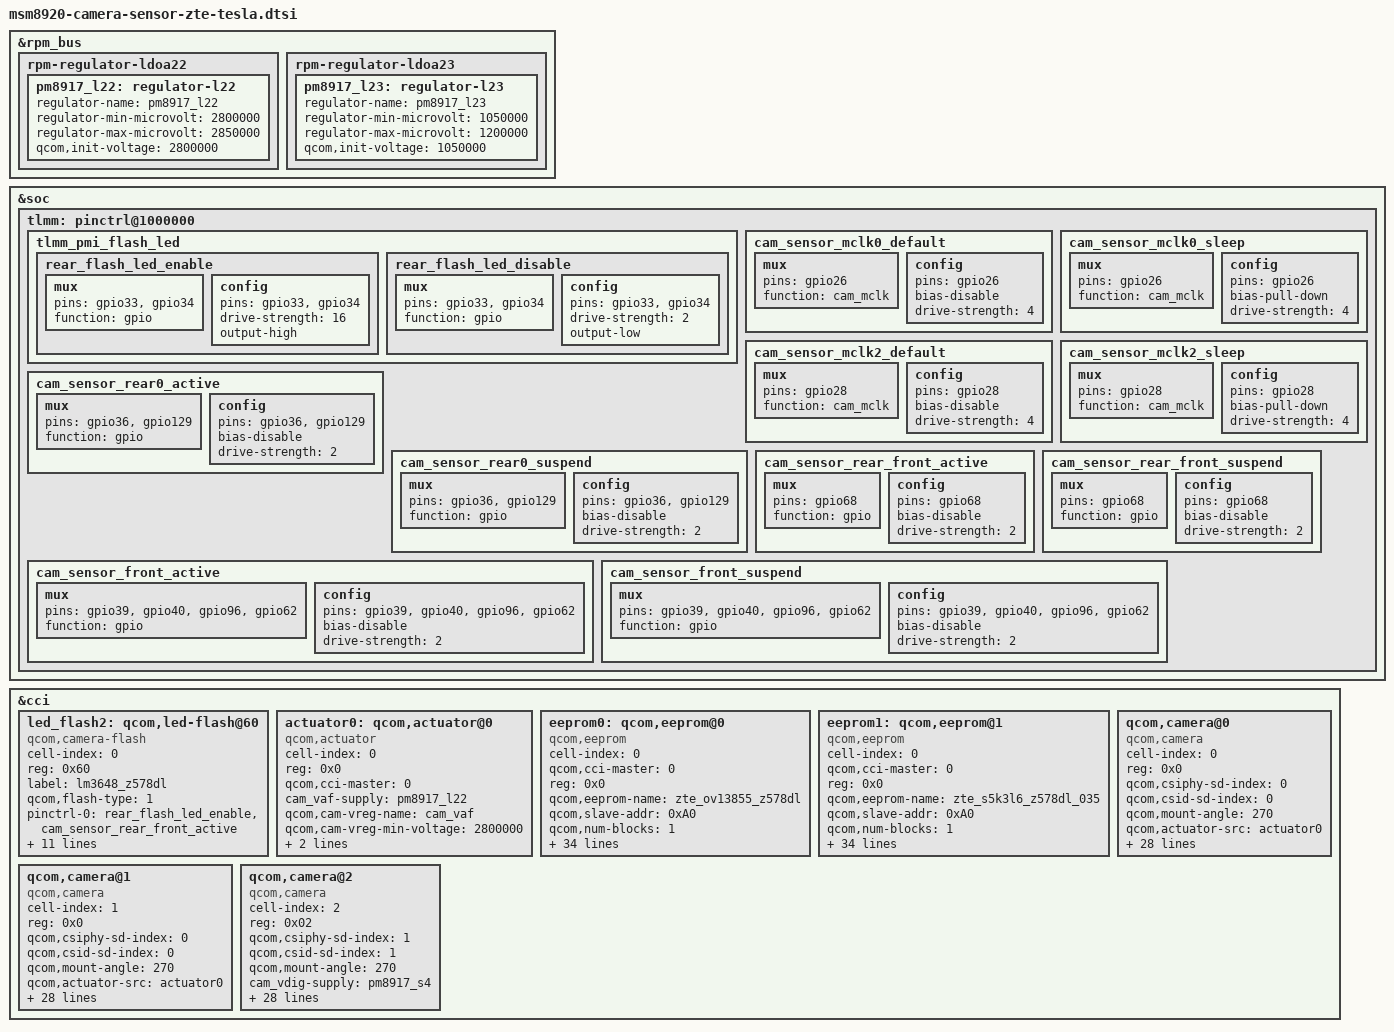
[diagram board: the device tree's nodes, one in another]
/*
* Copyright (c) 2015-2016, The Linux Foundation. All rights reserved.
*
* This program is free software; you can redistribute it and/or modify
* it under the terms of the GNU General Public License version 2 and
* only version 2 as published by the Free Software Foundation.
*
* This program is distributed in the hope that it will be useful,
* but WITHOUT ANY WARRANTY; without even the implied warranty of
* MERCHANTABILITY or FITNESS FOR A PARTICULAR PURPOSE.  See the
* GNU General Public License for more details.
*/
&rpm_bus {
	rpm-regulator-ldoa22 {
			status = "okay";
			pm8917_l22: regulator-l22 {
				regulator-name = "pm8917_l22";
				regulator-min-microvolt = <2800000>;
				regulator-max-microvolt = <2850000>;
				qcom,init-voltage = <2800000>;
				status = "okay";
			};
		};
		rpm-regulator-ldoa23 {
			status = "okay";
			pm8917_l23: regulator-l23 {
				regulator-name = "pm8917_l23";
				regulator-min-microvolt = <1050000>;
				regulator-max-microvolt = <1200000>;
				qcom,init-voltage = <1050000>;
				status = "okay";
			};
		};

};
&soc {
	tlmm: pinctrl@1000000 {
		tlmm_pmi_flash_led {
			rear_flash_led_enable: rear_flash_led_enable {
				mux {
					pins = "gpio33","gpio34";
					function = "gpio";
				};

				config {
					pins = "gpio33","gpio34";
					drive-strength = <16>;
					output-high;
				};
			};
			rear_flash_led_disable: rear_flash_led_disable {
				mux {
					pins = "gpio33","gpio34";
					function = "gpio";
				};

				config {
					pins = "gpio33","gpio34";
					drive-strength = <2>;
					output-low;
				};
			};
		};
		/*sensors */
	cam_sensor_mclk0_default: cam_sensor_mclk0_default {
		/* MCLK0 */
		mux {
			/* CLK, DATA */
			pins = "gpio26";
			function = "cam_mclk";
		};
		config {
			pins = "gpio26";
			bias-disable; /* No PULL */
			drive-strength = <4>; /* 4 MA */
		};
	};
	cam_sensor_mclk0_sleep: cam_sensor_mclk0_sleep {
		/* MCLK0 */
		mux {
			/* CLK, DATA */
			pins = "gpio26";
			function = "cam_mclk";
		};
		config {
			pins = "gpio26";
			bias-pull-down; /* PULL DOWN */
			drive-strength = <4>; /* 4 MA */
		};
	};
		cam_sensor_mclk2_default: cam_sensor_mclk2_default {
			/* MCLK2 */
			mux {
				/* CLK, DATA */
				pins = "gpio28";
				function = "cam_mclk";
			};
			config {
				pins = "gpio28";
				bias-disable; /* No PULL */
				drive-strength = <4>; /* 4 MA */
			};
		};
		cam_sensor_mclk2_sleep: cam_sensor_mclk2_sleep {
			/* MCLK2 */
			mux {
				/* CLK, DATA */
				pins = "gpio28";
				function = "cam_mclk";
			};
			config {
				pins = "gpio28";
				bias-pull-down; /* PULL DOWN */
				drive-strength = <4>; /* 4 MA */
			};
		};
		cam_sensor_rear0_active: cam_sensor_rear0_active {
			mux {
				pins = "gpio36",  "gpio129";
				function = "gpio";
			};

			config {
				pins = "gpio36",  "gpio129";
				bias-disable; /* No PULL */
				drive-strength = <2>; /* 2 MA */
			};
		};

		cam_sensor_rear0_suspend: cam_sensor_rear0_suspend{
			mux {
				pins = "gpio36",  "gpio129";
				function = "gpio";
			};

			config {
				pins = "gpio36", "gpio129";
				bias-disable; /* No PULL */
				drive-strength = <2>; /* 2 MA */
			};
		};

		cam_sensor_rear_front_active: cam_sensor_rear_front_active {
			mux {
				pins = "gpio68";
				function = "gpio";
			};

			config {
				pins = "gpio68";
				bias-disable; /* No PULL */
				drive-strength = <2>; /* 2 MA */
			};
		};

		cam_sensor_rear_front_suspend: cam_sensor_rear_front_suspend{
			mux {
				pins = "gpio68";
				function = "gpio";
			};

			config {
				pins = "gpio68";
				bias-disable; /* No PULL */
				drive-strength = <2>; /* 2 MA */
			};
		};
		cam_sensor_front_active: cam_sensor_front_active {
			mux {
				pins = "gpio39", "gpio40", "gpio96","gpio62";
				function = "gpio";
			};

			config {
				pins = "gpio39", "gpio40", "gpio96","gpio62";
				bias-disable; /* No PULL */
				drive-strength = <2>; /* 2 MA */
			};
		};

		cam_sensor_front_suspend: cam_sensor_front_suspend{
			mux {
				pins = "gpio39", "gpio40", "gpio96","gpio62";
				function = "gpio";
			};

			config {
				pins = "gpio39", "gpio40", "gpio96","gpio62";
				bias-disable; /* No PULL */
				drive-strength = <2>; /* 2 MA */
			};
		};
	};
};



&cci {
	led_flash2: qcom,led-flash@60{
		cell-index = <0>;
		compatible = "qcom,camera-flash";
		reg = <0x60>;
		label = "lm3648_z578dl";
		qcom,flash-type = <1>;
		pinctrl-names = "cam_default", "cam_suspend";
		pinctrl-0 = <&rear_flash_led_enable
				&cam_sensor_rear_front_active>;
		pinctrl-1 = <&rear_flash_led_disable
				&cam_sensor_rear_front_suspend>;
		gpios = <&tlmm 33 0>,
			<&tlmm 34 0>,
			<&tlmm 68 0>;
		qcom,gpio-flash-en = <0>;
		qcom,gpio-flash-now = <1>;
		qcom,gpio-flash-reset = <2>;
		qcom,gpio-req-tbl-num = <0 1 2>;
		qcom,gpio-req-tbl-flags = <0 0 0>;
		qcom,gpio-req-tbl-label = "FLASH_EN",
			"FLASH_NOW",
			"FLASH_RESET";
		qcom,cci-master = <0>;
	};
	actuator0: qcom,actuator@0 {
		cell-index = <0>;
		reg = <0x0>;
		compatible = "qcom,actuator";
		qcom,cci-master = <0>;
		cam_vaf-supply = <&pm8917_l22>;
		qcom,cam-vreg-name = "cam_vaf";
		qcom,cam-vreg-min-voltage = <2800000>;
		qcom,cam-vreg-max-voltage = <2850000>;
		qcom,cam-vreg-op-mode = <100000>;
	};
	eeprom0: qcom,eeprom@0 {
		cell-index = <0>;
		qcom,cci-master = <0>;
		reg = <0x0>;
		qcom,eeprom-name = "zte_ov13855_z578dl";
		compatible = "qcom,eeprom";
		qcom,slave-addr = <0xA0>;
		qcom,num-blocks = <1>;
		qcom,page0 = <0 0x0 2 0x0 1 0>;
		qcom,poll0 = <0 0x0 2 0x0 1 0>;
		qcom,mem0 = <3616 0x0000 2 0x0 1 0>;
		cam_vdig-supply = <&pm8917_l23>;
		qcom,cam-vreg-name ="cam_vaf","cam_vdig";
		qcom,cam-vreg-min-voltage = <2850000 1050000>;
		qcom,cam-vreg-max-voltage = <2850000 1050000>;
		qcom,cam-vreg-op-mode = <100000 105000>;
		pinctrl-names = "cam_default", "cam_suspend";
		pinctrl-0 = <&cam_sensor_mclk0_default
				&cam_sensor_rear_front_active
				&cam_sensor_rear0_active>;
		pinctrl-1 = <&cam_sensor_mclk0_sleep
				&cam_sensor_rear_front_suspend
				&cam_sensor_rear0_suspend>;
		gpios = <&tlmm 26 0>,
			<&tlmm 36 0>,
			<&tlmm 68 0>,
			<&tlmm 129 0>;
		qcom,gpio-reset = <1>;
		qcom,gpio-vio = <2>;
		qcom,gpio-vana = <3>;
		qcom,gpio-req-tbl-num = <0 1 2 3>;
		qcom,gpio-req-tbl-flags = <1 0 0 0>;
		qcom,gpio-req-tbl-label = "CAMIF_MCLK0",
			"CAM_RESET0",
			"CAM_VIO0",
			"CAM_VANA0";
		qcom,cam-power-seq-type = "sensor_gpio","sensor_gpio","sensor_gpio",
			"sensor_vreg","sensor_vreg","sensor_clk","sensor_gpio";
		qcom,cam-power-seq-val = "sensor_gpio_reset","sensor_gpio_vana","sensor_gpio_vio",
			"cam_vdig","cam_vaf","sensor_cam_mclk","sensor_gpio_reset";
		qcom,cam-power-seq-cfg-val = <0 1 1 0 0 24000000 1>;
		qcom,cam-power-seq-delay = <1 0 0 0 1 1 10>;
		status = "ok";
		clocks = <&clock_gcc clk_mclk0_clk_src>,
				<&clock_gcc clk_gcc_camss_mclk0_clk>;
		clock-names = "cam_src_clk", "cam_clk";
		qcom,clock-rates = <24000000 0>;
	};
	eeprom1: qcom,eeprom@1 {
		cell-index = <0>;
		qcom,cci-master = <0>;
		reg = <0x0>;
		qcom,eeprom-name = "zte_s5k3l6_z578dl_035";
		compatible = "qcom,eeprom";
		qcom,slave-addr = <0xA0>;
		qcom,num-blocks = <1>;
		qcom,page0 = <0 0x0 2 0x0 1 0>;
		qcom,poll0 = <0 0x0 2 0x0 1 0>;
		qcom,mem0 = <3616 0x0000 2 0x0 1 0>;
		cam_vdig-supply = <&pm8917_l23>;
		qcom,cam-vreg-name ="cam_vaf","cam_vdig";
		qcom,cam-vreg-min-voltage = <2850000 1050000>;
		qcom,cam-vreg-max-voltage = <2850000 1050000>;
		qcom,cam-vreg-op-mode = <100000 105000>;
		pinctrl-names = "cam_default", "cam_suspend";
		pinctrl-0 = <&cam_sensor_mclk0_default
				&cam_sensor_rear_front_active
				&cam_sensor_rear0_active>;
		pinctrl-1 = <&cam_sensor_mclk0_sleep
				&cam_sensor_rear_front_suspend
				&cam_sensor_rear0_suspend>;
		gpios = <&tlmm 26 0>,
			<&tlmm 36 0>,
			<&tlmm 68 0>,
			<&tlmm 129 0>;
		qcom,gpio-reset = <1>;
		qcom,gpio-vio = <2>;
		qcom,gpio-vana = <3>;
		qcom,gpio-req-tbl-num = <0 1 2 3>;
		qcom,gpio-req-tbl-flags = <1 0 0 0>;
		qcom,gpio-req-tbl-label = "CAMIF_MCLK0",
			"CAM_RESET0",
			"CAM_VIO0",
			"CAM_VANA0";
		qcom,cam-power-seq-type = "sensor_gpio","sensor_gpio","sensor_gpio",
			"sensor_vreg","sensor_vreg","sensor_clk","sensor_gpio";
		qcom,cam-power-seq-val = "sensor_gpio_reset","sensor_gpio_vana","sensor_gpio_vio",
			"cam_vdig","cam_vaf","sensor_cam_mclk","sensor_gpio_reset";
		qcom,cam-power-seq-cfg-val = <0 1 1 0 0 24000000 1>;
		qcom,cam-power-seq-delay = <1 0 0 0 1 1 10>;
		status = "ok";
		clocks = <&clock_gcc clk_mclk0_clk_src>,
				<&clock_gcc clk_gcc_camss_mclk0_clk>;
		clock-names = "cam_src_clk", "cam_clk";
		qcom,clock-rates = <24000000 0>;
	};
	qcom,camera@0 {
		cell-index = <0>;
		compatible = "qcom,camera";
		reg = <0x0>;
		qcom,csiphy-sd-index = <0>;
		qcom,csid-sd-index = <0>;
		qcom,mount-angle = <270>;
		qcom,actuator-src = <&actuator0>;
		qcom,led-flash-src = <&led_flash2>;
		qcom,eeprom-src = <&eeprom1>;
		cam_vaf-supply = <&pm8917_l22>;
		cam_vdig-supply = <&pm8917_l23>;
		qcom,cam-vreg-name ="cam_vaf","cam_vdig";
		qcom,cam-vreg-min-voltage = <2850000 1050000>;
		qcom,cam-vreg-max-voltage = <2850000 1050000>;
		qcom,cam-vreg-op-mode = <100000 105000>;
		pinctrl-names = "cam_default", "cam_suspend";
		pinctrl-0 = <&cam_sensor_mclk0_default
				&cam_sensor_rear_front_active
				&cam_sensor_rear0_active>;
		pinctrl-1 = <&cam_sensor_mclk0_sleep
				&cam_sensor_rear_front_suspend
				&cam_sensor_rear0_suspend>;
		gpios = <&tlmm 26 0>,
			<&tlmm 36 0>,
			<&tlmm 68 0>,
			<&tlmm 129 0>;
		qcom,gpio-reset = <1>;
		qcom,gpio-vio = <2>;
		qcom,gpio-vana = <3>;
		qcom,gpio-req-tbl-num = <0 1 2 3>;
		qcom,gpio-req-tbl-flags = <1 0 0 0>;
		qcom,gpio-req-tbl-label = "CAMIF_MCLK0",
			"CAM_RESET0",
			"CAM_VIO0",
			"CAM_VANA0";
		qcom,sensor-position = <0>;
		qcom,sensor-mode = <0>;
		qcom,cci-master = <0>;
		status = "ok";
		clocks = <&clock_gcc clk_mclk0_clk_src>,
				<&clock_gcc clk_gcc_camss_mclk0_clk>;
		clock-names = "cam_src_clk", "cam_clk";
		qcom,clock-rates = <24000000 0>;
	};
	qcom,camera@1{
		cell-index = <1>;
		compatible = "qcom,camera";
		reg = <0x0>;
		qcom,csiphy-sd-index = <0>;
		qcom,csid-sd-index = <0>;
		qcom,mount-angle = <270>;
		qcom,actuator-src = <&actuator0>;
		qcom,led-flash-src = <&led_flash2>;
		qcom,eeprom-src = <&eeprom0>;
		cam_vaf-supply = <&pm8917_l22>;
		cam_vdig-supply = <&pm8917_l23>;
		qcom,cam-vreg-name ="cam_vaf","cam_vdig";
		qcom,cam-vreg-min-voltage = <2850000 1200000>;
		qcom,cam-vreg-max-voltage = <2850000 1200000>;
		qcom,cam-vreg-op-mode = <100000 105000>;
		pinctrl-names = "cam_default", "cam_suspend";
		pinctrl-0 = <&cam_sensor_mclk0_default
				&cam_sensor_rear_front_active
				&cam_sensor_rear0_active>;
		pinctrl-1 = <&cam_sensor_mclk0_sleep
				&cam_sensor_rear_front_suspend
				&cam_sensor_rear0_suspend>;
		gpios = <&tlmm 26 0>,
			<&tlmm 36 0>,
			<&tlmm 68 0>,
			<&tlmm 129 0>;
		qcom,gpio-reset = <1>;
		qcom,gpio-vio = <2>;
		qcom,gpio-vana = <3>;
		qcom,gpio-req-tbl-num = <0 1 2 3>;
		qcom,gpio-req-tbl-flags = <1 0 0 0>;
		qcom,gpio-req-tbl-label = "CAMIF_MCLK0",
			"CAM_RESET0",
			"CAM_VIO0",
			"CAM_VANA0";
		qcom,sensor-position = <0>;
		qcom,sensor-mode = <0>;
		qcom,cci-master = <0>;
		status = "ok";
		clocks = <&clock_gcc clk_mclk0_clk_src>,
				<&clock_gcc clk_gcc_camss_mclk0_clk>;
		clock-names = "cam_src_clk", "cam_clk";
		qcom,clock-rates = <24000000 0>;
	};
	qcom,camera@2 {
		cell-index = <2>;
		compatible = "qcom,camera";
		reg = <0x02>;
		qcom,csiphy-sd-index = <1>;
		qcom,csid-sd-index = <1>;
		qcom,mount-angle = <270>;
		cam_vdig-supply = <&pm8917_s4>;
		qcom,cam-vreg-name = "cam_vdig";
		qcom,cam-vreg-min-voltage = <2050000>;
		qcom,cam-vreg-max-voltage = <2050000>;
		qcom,cam-vreg-op-mode = <105000>;
		pinctrl-names = "cam_default", "cam_suspend";
		pinctrl-0 = <&cam_sensor_mclk2_default
				&cam_sensor_rear_front_active
				&cam_sensor_front_active>;
		pinctrl-1 = <&cam_sensor_mclk2_sleep
				&cam_sensor_rear_front_suspend
				&cam_sensor_front_suspend>;
		gpios = <&tlmm 28 0>,
			<&tlmm 40 0>,
			<&tlmm 39 0>,
			<&tlmm 68 0>,
			<&tlmm 96 0>,
			<&tlmm 62 0>;

		qcom,gpio-reset = <1>;
		qcom,gpio-standby = <2>;
		qcom,gpio-vio = <3>;
		qcom,gpio-vana = <4>;
		qcom,gpio-vdig = <5>;
		qcom,gpio-req-tbl-num = <0 1 2 3 4 5>;
		qcom,gpio-req-tbl-flags = <1 0 0 0 0 0>;
		qcom,gpio-req-tbl-label = "CAMIF_MCLK2",
					  "CAM_RESET2",
					  "CAM_STANDBY2",
					  "CAM_VIO2",
					  "CAM_VANA2",
					  "CAM_VDIG2";
		qcom,sensor-position = <1>;
		qcom,sensor-mode = <0>;
		qcom,cci-master = <0>;
		status = "ok";
		clocks = <&clock_gcc clk_mclk2_clk_src>,
			<&clock_gcc clk_gcc_camss_mclk2_clk>;
		clock-names = "cam_src_clk", "cam_clk";
		qcom,clock-rates = <24000000 0>;
	};
};
